# AM13E230x register map
Vendor: Texas Instruments; File version: Revised: 2025-12-26 17:30:06
CPU: CM33 r0p0, little endian, MPU, FPU, 4 interrupt priority bits
Registers are 32-bit, read-write, reset 0x0 unless marked. A register's access mark holds for its fields unless they carry their own. Offsets are from the block's base; [hi:lo] are bit positions; {n}, {i} and the like mark numbered series.

## ECAP0 — ECAP_REGS
Base 0x40440000
Same registers: ECAP1 0x40441000
0x00 TSCTR — Time-Stamp Counter
0x04 CTRPHS — Counter Phase Offset Value Register
{0x4+4i} CAP{i} (i=1..4) — Capture {i} Register
0x24 ECCTL0 reset 0x7F — Capture Control Register 0
  [6:0] INPUTSEL — INPUT source select
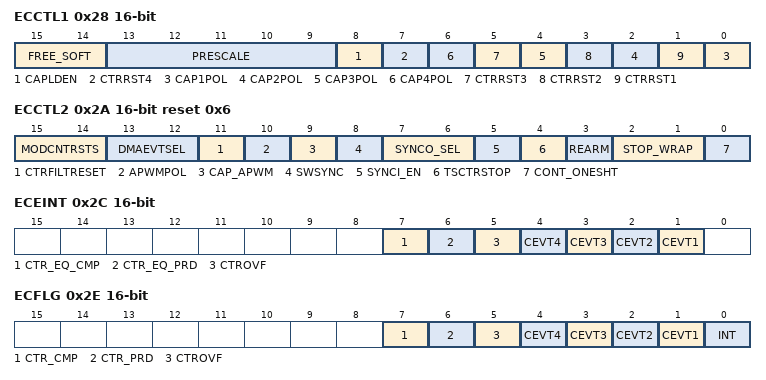
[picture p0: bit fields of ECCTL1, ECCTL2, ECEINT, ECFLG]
0x28 ECCTL1 16-bit — Capture Control Register 1
  [15:14] FREE_SOFT — Emulation mode
    0=ECap_stop_emu (TSCTR counter stops immediately on emulation suspend); 1=ECap_runs_until (TSCTR counter runs until = 0); 2=ECap_unaf_emu_sus (TSCTR counter is unaffected by emulation suspend (Run Free)); 3=ECap_unaf_emu_sus2 (TSCTR counter is unaffected by emulation suspend (Run Free))
  [13:9] PRESCALE — Event Filter prescale select
    0=Ecap_div1 (Divide by 1 (i.e,. no prescale, by-pass the prescaler)); 1=Ecap_div2 (Divide by 2); 2=Ecap_div4 (Divide by 4); 3=Ecap_div6 (Divide by 6); 4=Ecap_div8 (Divide by 8); 5=Ecap_div10 (Divide by 10); 30=Ecap_div60 (Divide by 60); 31=Ecap_div62 (Divide by 62)
  [8] CAPLDEN — Enable Loading CAP1-4 regs on a Cap Event
    0=Ecap_Disable (Disable CAP1-4 register loads at capture event time.); 1=Ecap_Enable (Enable CAP1-4 register loads at capture event time.)
  [7] CTRRST4 — Counter Reset on Capture Event 4
    0=Ecap_do_not_reset_event4 (Do not reset counter on Capture Event 4 (absolute time stamp operation)); 1=Ecap_reset_event4 (Reset counter after Capture Event 4 time-stamp has been captured (used in difference mode operation))
  [2n-2] CAP{n}POL (n=1..4) — Capture Event {n} Polarity select
    0=Ecap_cap_event{n}_rise (Capture Event {n} triggered on a rising edge (RE)); 1=Ecap_cap_event{n}_fall (Capture Event {n} triggered on a falling edge (FE))
  [5] CTRRST3 — Counter Reset on Capture Event 3
    0=Ecap_do_not_reset_event3 (Do not reset counter on Capture Event 3 (absolute time stamp)); 1=Ecap_reset_event3 (Reset counter after Event 3 time-stamp has been captured (used in difference mode operation))
  [3] CTRRST2 — Counter Reset on Capture Event 2
    0=Ecap_do_not_reset_event2 (Do not reset counter on Capture Event 2 (absolute time stamp)); 1=Ecap_reset_event2 (Reset counter after Event 2 time-stamp has been captured (used in difference mode operation))
  [1] CTRRST1 — Counter Reset on Capture Event 1
    0=Ecap_do_not_reset_event1 (Do not reset counter on Capture Event 1 (absolute time stamp)); 1=Ecap_reset_event1 (Reset counter after Event 1 time-stamp has been captured (used in difference mode operation))
0x2A ECCTL2 16-bit reset 0x6 — Capture Control Register 2
  [15:14] MODCNTRSTS ro — modulo counter status
  [13:12] DMAEVTSEL — DMA event select
  [11] CTRFILTRESET — Reset event filter, modulus counter, and interrupt flags.
  [10] APWMPOL — APWM output polarity select
    0=Ecap_output_active_high (Output is active high (Compare value defines high time)); 1=Ecap_output_active_low (Output is active low (Compare value defines low time))
  [9] CAP_APWM — CAP/APWM operating mode select
    0=ECAP module operates in capture mode. This mode forces the following configuration: #br#- Inhibits TSCTR resets via CTR = PRD event #br#- Inhibits shadow loads on CAP1 and 2 registers #br#- Permits user to enable CAP1-4 register load #br#- CAPx/APWMx pin operates as a capture input; 1=Ecap_module_APWM (ECAP module operates in APWM mode. This mode forces the following configuration: #br#- Resets TSCTR on CTR = PRD event (period boundary #br#- Permits shadow loading on CAP1 and 2 registers #br#- Disables loading of time-stamps into CAP1-4 registers #br#- CAPx/APWMx pin operates as a APWM output)
  [8] SWSYNC — SW forced counter sync
    0=Ecap_zero_noeffect (Writing a zero has no effect. Reading always returns a zero); 1=Ecap_write_TSCTR (Writing a one forces a TSCTR shadow load of current ECAP module and any ECAP modules down-stream providing the SYNCO_SEL bits are 0,0. After writing a 1, this bit returns to a zero.)
  [7:6] SYNCO_SEL — Sync-out mode
    0=SWSYNC (sync out signal is SWSYNC); 1=Ecap_CTR_PRD_to_syncout (Select CTR = PRD event to be the sync-out signal. Note: Selection CTR = PRD is meaningful only in APWM mode); 2=Ecap_disable_sync_out (Disable sync out signal); 3=Ecap_disable_sync_out (Disable sync out signal)
  [5] SYNCI_EN — Counter sync-in select
    0=Ecap_disable_sync_in (Disable sync-in option); 1=Ecap_enable_counter_register (Enable counter (TSCTR) to be loaded from CTRPHS register upon either a SYNCI signal or a S/W force event.)
  [4] TSCTRSTOP — TSCNT counter stop
    0=Ecap_TSCTR_stopped (TSCTR stopped); 1=Ecap_TSCTR_free_running (TSCTR free-running)
  [3] REARM — One-shot re-arm
    0=Ecap_no_effect_returns_0 (Has no effect (reading always returns a 0)); 1=Ecap_arms_oneshot (Arms the one-shot sequence as follows: #br#1) Resets the Mod4 counter to zero #br#2) Unfreezes the Mod4 counter #br#3) Enables capture register loads)
  [2:1] STOP_WRAP — Stop value for one-shot, Wrap for continuous
    {v}=Ecap_StopEvent{v+1}_WrapEvent2 (Stop after Capture Event {v+1} in one-shot mode #br#Wrap after Capture Event {v+1} in continuous mode.) (v=0..3)
  [0] CONT_ONESHT — Continuous or one-shot
    0=Ecap_opp_cont (Operate in continuous mode); 1=Ecap_opp_one (Operate in one-Shot mode)
0x2C ECEINT 16-bit — Capture Interrupt Enable Register
  [7] CTR_EQ_CMP — Compare Equal Interrupt Enable
    0=Ecap_disab_CE_interrupt (Disable Compare Equal as an Interrupt source); 1=Ecap_enab_CE_interrupt (Enable Compare Equal as an Interrupt source)
  [6] CTR_EQ_PRD — Period Equal Interrupt Enable
    0=Ecap_disab_PE_interrupt (Disable Period Equal as an Interrupt source); 1=Ecap_enab_PE_interrupt (Enable Period Equal as an Interrupt source)
  [5] CTROVF — Counter Overflow Interrupt Enable
    0=Ecap_disab_CO_interrupt (Disabled counter Overflow as an Interrupt source); 1=Ecap_enab_CO_interrupt (Enable counter Overflow as an Interrupt source)
  [4] CEVT4 — Capture Event 4 Interrupt Enable
    0=Ecap_disab_Cap4_interrupt (Disable Capture Event 4 as an Interrupt source); 1=Ecap_enab_Cap4_interrupt (Capture Event 4 Interrupt Enable)
  [3] CEVT3 — Capture Event 3 Interrupt Enable
    0=Ecap_disab_Cap3_interrupt (Disable Capture Event 3 as an Interrupt source); 1=Ecap_enab_Cap3_interrupt (Enable Capture Event 3 as an Interrupt source)
  [2] CEVT2 — Capture Event 2 Interrupt Enable
    0=Ecap_disab_Cap2_interrupt (Disable Capture Event 2 as an Interrupt source); 1=Ecap_enab_Cap2_interrupt (Enable Capture Event 2 as an Interrupt source)
  [1] CEVT1 — Capture Event 1 Interrupt Enable
    0=Ecap_disab_Cap1_interrupt (Disable Capture Event 1 as an Interrupt source); 1=Ecap_enab_Cap1_interrupt (Enable Capture Event 1 as an Interrupt source)
0x2E ECFLG 16-bit — Capture Interrupt Flag Register
  [7] CTR_CMP ro — Compare Equal Interrupt Flag
    0=Ecap_indicate_no_event (Indicates no event occurred); 1=Ecap_indicate_counter_compare_reg (Indicates the counter (TSCTR) reached the compare register value (ACMP))
  [6] CTR_PRD ro — Period Equal Interrupt Flag
    0=Ecap_indicate_no_event (Indicates no event occurred); 1=Ecap_indicate_period_value_reset (Indicates the counter (TSCTR) reached the period register value (APRD) and was reset.)
  [5] CTROVF ro — Counter Overflow Interrupt Flag
    0=Ecap_indicate_no_event (Indicates no event occurred); 1=Ecap_indicate_counter_trans (Indicates the counter (TSCTR) has made the transition from FFFFFFFF to 00000000)
  [4] CEVT4 ro — Capture Event 4 Interrupt Flag
    0=Ecap_indicate_no_event (Indicates no event occurred); 1=Ecap_indicate_4th_event_ECAPx (Indicates the fourth event occurred at ECAPx pin)
  [3] CEVT3 ro — Capture Event 3 Interrupt Flag
    0=Ecap_indicate_no_event (Indicates no event occurred); 1=Ecap_indicate_3rd_event_ECAPx (Indicates the third event occurred at ECAPx pin.)
  [2] CEVT2 ro — Capture Event 2 Interrupt Flag
    0=Ecap_indicate_no_event (Indicates no event occurred); 1=Ecap_indicate_2nd_event_ECAPx (Indicates the second event occurred at ECAPx pin.)
  [1] CEVT1 ro — Capture Event 1 Interrupt Flag
    0=Ecap_indicate_no_event (Indicates no event occurred); 1=Ecap_indicate_1st_event_ECAPx (Indicates the first event occurred at ECAPx pin.)
  [0] INT ro — Global Flag
    0=Ecap_indicate_no_event (Indicates no event occurred); 1=Ecap_indicate_interrupt (Indicates that an interrupt was generated.)
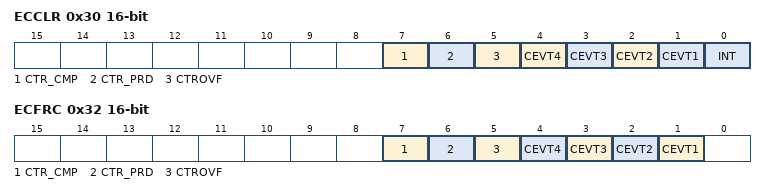
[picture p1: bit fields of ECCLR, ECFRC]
0x30 ECCLR 16-bit — Capture Interrupt Clear Register
  [7] CTR_CMP — Compare Equal Status Clear
    0=Ecap_0_no_effect (Writing a 0 has no effect. Always reads back a 0); 1=Ecap_1_clears_CTR_CMP (Writing a 1 clears the CTR=CMP flag.)
  [6] CTR_PRD — Period Equal Status Clear
    0=Ecap_0_no_effect (Writing a 0 has no effect. Always reads back a 0); 1=Ecap_1_clears_CTR_PRD (Writing a 1 clears the CTR=PRD flag.)
  [5] CTROVF — Counter Overflow Status Clear
    0=Ecap_0_no_effect (Writing a 0 has no effect. Always reads back a 0); 1=Ecap_1_clears_CTROVF (Writing a 1 clears the CTROVF flag.)
  [n] CEVT{n} (n=1..4) — Capture Event {n} Status Clear
    0=Ecap_0_no_effect (Writing a 0 has no effect. Always reads back a 0); 1=Ecap_1_clears_CEVT{n} (Writing a 1 clears the CEVT{n} flag.)
  [0] INT — ECAP Global Interrupt Status Clear
    0=Ecap_0_no_effect (Writing a 0 has no effect. Always reads back a 0); 1=Ecap_1_clears_INT (Writing a 1 clears the INT flag and enable further interrupts to be generated if any of the event flags are set to 1)
0x32 ECFRC 16-bit — Capture Interrupt Force Register
  [7] CTR_CMP — Compare Equal Force Interrupt
    0=Ecap_no_effect_0 (No effect. Always reads back a 0.); 1=Ecap_1_sets_CTR_CMP (Writing a 1 sets the CTR_CMP flag.)
  [6] CTR_PRD — Period Equal Force Interrupt
    0=Ecap_no_effect_0 (No effect. Always reads back a 0.); 1=Ecap_1_clears_CTR_PRD (Writing a 1 sets the CTR_PRD flag.)
  [5] CTROVF — Counter Overflow Force Interrupt
    0=Ecap_no_effect_0 (No effect. Always reads back a 0.); 1=Ecap_1_sets_CTROVF (Writing a 1 to this bit sets the CTROVF flag.)
  [4] CEVT4 — Capture Event 4 Force Interrupt
    0=Ecap_no_effect_0 (No effect. Always reads back a 0.); 1=Ecap_1_sets_CEVT4 (Writing a 1 sets the CEVT4 flag.)
  [3] CEVT3 — Capture Event 3 Force Interrupt
    0=Ecap_no_effect_0 (No effect. Always reads back a 0.); 1=Ecap_1_sets_CEVT3 (Writing a 1 sets the CEVT3 flag.)
  [2] CEVT2 — Capture Event 2 Force Interrupt
    0=Ecap_no_effect_0 (No effect. Always reads back a 0.); 1=Ecap_1_sets_CEVT2 (Writing a 1 sets the CEVT2 flag.)
  [1] CEVT1 — Capture Event 1 Force Interrupt
    0=Ecap_no_effect_0 (No effect. Always reads back a 0.); 1=Ecap_1_sets_CEVT1 (Sets the CEVT1 flag.)
0x3C ECAPSYNCINSEL reset 0x1 — SYNC source select register
  [4:0] SEL — SYNCIN source select
